# BAT32A237 register map
Vendor: CMS; Series: BAT32A237; File version: 1.2
CPU: CM0+ r0p1, little endian, MPU, no FPU, VTOR, 2 interrupt priority bits
Registers are 8-bit, read-write, reset 0x0 unless marked. A register's access mark holds for its fields unless they carry their own. Offsets are from the block's base; [hi:lo] are bit positions; 'fields as' and 'values as' point back to an identical list.

## PCBZ — Clock/Buzzer output controller
Base 0x40040FA0
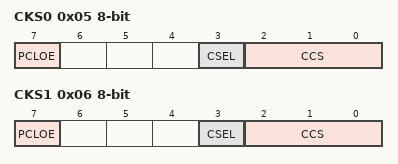
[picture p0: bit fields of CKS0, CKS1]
0x05 CKS0 — Clock output select registers 0
  [7] PCLOE — PCLBUZn pin output enable
  [3] CSEL — PCLBUZn output clock select
  [2:0] CCS — PCLBUZn output clock select
0x06 CKS1 — Clock output select registers 1
  fields as CKS0

## WDT — Watchdog Timer with window
Base 0x40021000
0x01 WDTE (reset mask 0xAC) — Watchdog timer enable register

## ADC — A/D Converter
Base 0x40045000
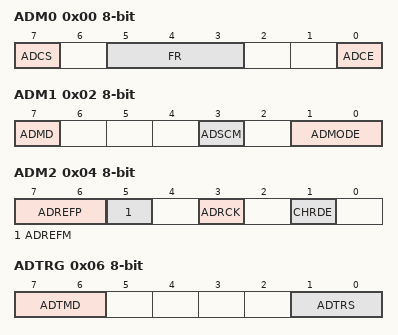
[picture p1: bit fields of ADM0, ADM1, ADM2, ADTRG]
0x00 ADM0 — A/D mode register 0
  [7] ADCS — A/D conversion operation control
  [5:3] FR — A/D conversion clock (fAD) select
  [0] ADCE — A/D enable
0x02 ADM1 — A/D mode register 1
  [7] ADMD — A/D conversion channel select mode
    0=Select mode; 1=Scan mode
  [3] ADSCM — A/D conversion mode
    0=Sequential conversion mode; 1=One-shot conversion mode
  [1:0] ADMODE — A/D mode select
0x04 ADM2 — A/D mode register 2
  [7:6] ADREFP — Selection of the + side reference voltage of A/D converter
    0=VDD (Supplied from VDD); 1=AVREFP0 (Supplied from AVREFP); 2=AVREFP1 (Supplied from inside AVREF of A/D)
  [5] ADREFM — Selection of the - side reference voltage of A/D converter
    0=VSS (Supplied from VSS); 1=AVREFM (Supplied from AVREFM)
  [3] ADRCK — the upper limit and lower limit conversion result values
  [1] CHRDE — output CH number in A/D conversion result in Scan mode
0x06 ADTRG (reset mask 0x33) — A/D mode register 2
  [7:6] ADTMD — A/D conversion trigger mode
  [1:0] ADTRS — A/D hard trigger select
0x08 ADS — Analog input channel specification register
0x0A ADLL — Conversion result comparison lower limit setting register
0x0B ADUL reset 0xFF — Conversion result comparison upper limit setting register
0x0C ADNSMP — A/D sampling time control register
0x0E ADCR 16-bit (reset mask 0xFFF) — 12-bit A/D conversion result register
0x0F ADCRH (alternate view of ADCR) — Higher 8-bit A/D conversion result register
0x10 ADTES (reset mask 0x7) — A/D test register
0x11 ADNDIS — A/D charge/discharge control register
0x15 ADSMPWAIT — A/D sampling wait control register
0x16 ADFLG (reset mask 0x1F) — A/D flag register

## DAC — D/A Converter
Base 0x40044700
0x34 DACS0 — D/A conversion value setting register 0
0x35 DACS1 — D/A conversion value setting register 1
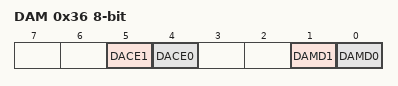
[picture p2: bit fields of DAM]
0x36 DAM — D/A conversion mode register
  [5] DACE1 — D/A converter operation control
  [4] DACE0 — D/A converter operation control
  [1] DAMD1 — D/A converter operation mode selection
  [0] DAMD0 — D/A converter operation mode selection

## CMP — Comparator
Base 0x40043840
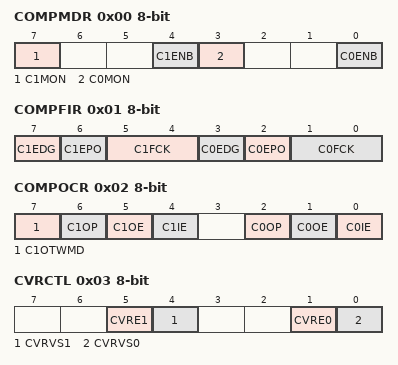
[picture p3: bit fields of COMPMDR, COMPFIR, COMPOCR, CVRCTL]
0x00 COMPMDR — Comparator mode setting register
  [7] C1MON — Comparator 1 monitor flag
  [4] C1ENB — Comparator 1 operation enable
  [3] C0MON — Comparator 0 monitor flag
  [0] C0ENB — Comparator 0 operation enable
0x01 COMPFIR — Comparator filter control register
  [7] C1EDG — Comparator 1 edge detection selection
  [6] C1EPO — Comparator 1 edge polarity switching
  [5:4] C1FCK — Comparator 1 filter selection
  [3] C0EDG — Comparator 0 edge detection selection
  [2] C0EPO — Comparator 0 edge polarity switching
  [1:0] C0FCK — Comparator 0 filter selection
0x02 COMPOCR — Comparator output control register
  [7] C1OTWMD — TIMER WINDOW output mode control bit of comparator 1
  [6] C1OP — VOUT1 output polarity selection
  [5] C1OE — VOUT1 pin output enable
  [4] C1IE — Comparator 1 interrupt request enable
  [2] C0OP — VOUT0 output polarity selection
  [1] C0OE — VOUT0 pin output enable
  [0] C0IE — Comparator 0 interrupt request enable
0x03 CVRCTL — Comparator internal reference voltage control register
  [5] CVRE1 — Control bit for internal reference voltage 1
  [4] CVRVS1 — Ground selection bit for internal reference voltage
  [1] CVRE0 — Control bit for internal reference voltage 0
  [0] CVRVS0 — Power supply selection bit for internal reference voltage
0x04 C0RVM — Comparator internal reference voltage select register 0
0x05 C1RVM — Comparator internal reference voltage select register 1
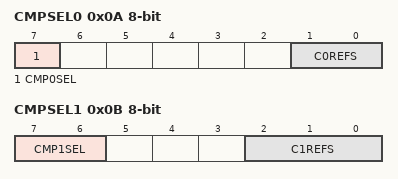
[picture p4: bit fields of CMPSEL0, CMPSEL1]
0x0A CMPSEL0 — Comparator 0 input signal selection control register
  [7] CMP0SEL — Selection of the input signal on the positive side of Comparator 0
  [1:0] C0REFS — Selection of the input signal on the negative side of Comparator 0
0x0B CMPSEL1 — Comparator 1 input signal selection control register
  [7:6] CMP1SEL — Selection of the input signal on the positive side of Comparator 1
  [2:0] C1REFS — Selection of the input signal on the negative side of Comparator 1
